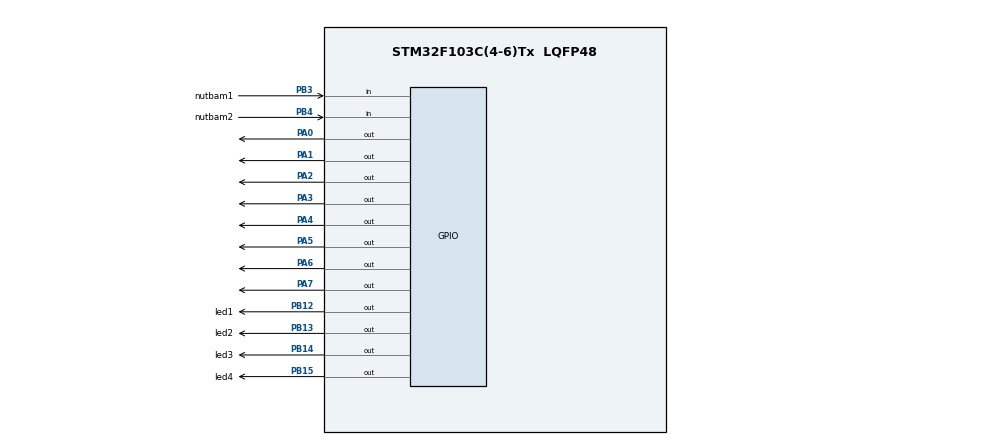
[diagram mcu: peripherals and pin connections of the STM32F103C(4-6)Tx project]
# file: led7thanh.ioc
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Mcu.Family=STM32F1
Mcu.Name=STM32F103C(4-6)Tx
Mcu.Package=LQFP48
NVIC.PriorityGroup=NVIC_PRIORITYGROUP_4
PA0-WKUP.Signal=GPIO_Output
PA1.Signal=GPIO_Output
PA13.Mode=Serial_Wire
PA13.Signal=SYS_JTMS-SWDIO
PA14.Mode=Serial_Wire
PA14.Signal=SYS_JTCK-SWCLK
PA2.Signal=GPIO_Output
PA3.Signal=GPIO_Output
PA4.Signal=GPIO_Output
PA5.Signal=GPIO_Output
PA6.Signal=GPIO_Output
PA7.Signal=GPIO_Output
PB12.GPIO_Label=led1
PB12.PinState=GPIO_PIN_SET
PB12.Signal=GPIO_Output
PB13.GPIO_Label=led2
PB13.PinState=GPIO_PIN_SET
PB13.Signal=GPIO_Output
PB14.GPIO_Label=led3
PB14.PinState=GPIO_PIN_SET
PB14.Signal=GPIO_Output
PB15.GPIO_Label=led4
PB15.PinState=GPIO_PIN_SET
PB15.Signal=GPIO_Output
PB3.GPIO_Label=nutbam1
PB3.Signal=GPIO_Input
PB4.GPIO_Label=nutbam2
PB4.Signal=GPIO_Input
ProjectManager.HeapSize=0x200
ProjectManager.StackSize=0x400
ProjectManager.TargetToolchain=MDK-ARM V5
RCC.APB1Freq_Value=8000000
RCC.APB2Freq_Value=8000000
board=custom

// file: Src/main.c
/**
  ******************************************************************************
  * @file           : main.c
  * @brief          : Main program body
  ******************************************************************************
  ** This notice applies to any and all portions of this file
  * that are not between comment pairs USER CODE BEGIN and
  * USER CODE END. Other portions of this file, whether
  * inserted by the user or by software development tools
  * are owned by their respective copyright owners.
  *
  * COPYRIGHT(c) 2018 STMicroelectronics
  *
  * Redistribution and use in source and binary forms, with or without modification,
  * are permitted provided that the following conditions are met:
  *   1. Redistributions of source code must retain the above copyright notice,
  *      this list of conditions and the following disclaimer.
  *   2. Redistributions in binary form must reproduce the above copyright notice,
  *      this list of conditions and the following disclaimer in the documentation
  *      and/or other materials provided with the distribution.
  *   3. Neither the name of STMicroelectronics nor the names of its contributors
  *      may be used to endorse or promote products derived from this software
  *      without specific prior written permission.
  *
  * THIS SOFTWARE IS PROVIDED BY THE COPYRIGHT HOLDERS AND CONTRIBUTORS "AS IS"
  * AND ANY EXPRESS OR IMPLIED WARRANTIES, INCLUDING, BUT NOT LIMITED TO, THE
  * IMPLIED WARRANTIES OF MERCHANTABILITY AND FITNESS FOR A PARTICULAR PURPOSE ARE
  * DISCLAIMED. IN NO EVENT SHALL THE COPYRIGHT HOLDER OR CONTRIBUTORS BE LIABLE
  * FOR ANY DIRECT, INDIRECT, INCIDENTAL, SPECIAL, EXEMPLARY, OR CONSEQUENTIAL
  * DAMAGES (INCLUDING, BUT NOT LIMITED TO, PROCUREMENT OF SUBSTITUTE GOODS OR
  * SERVICES; LOSS OF USE, DATA, OR PROFITS; OR BUSINESS INTERRUPTION) HOWEVER
  * CAUSED AND ON ANY THEORY OF LIABILITY, WHETHER IN CONTRACT, STRICT LIABILITY,
  * OR TORT (INCLUDING NEGLIGENCE OR OTHERWISE) ARISING IN ANY WAY OUT OF THE USE
  * OF THIS SOFTWARE, EVEN IF ADVISED OF THE POSSIBILITY OF SUCH DAMAGE.
  *
  ******************************************************************************
  */
#include "main.h"
#include "stm32f1xx_hal.h"

/* USER CODE BEGIN PV */
/* Private variables ---------------------------------------------------------*/

uint8_t ledCode[10] = {0xC0, 0xF9, 0xA4, 0xB0, 0x99, 0x92, 0x82, 0xF8, 0x80, 0x90};

/* USER CODE END PV */

void SystemClock_Config(void);
static void MX_GPIO_Init(void);

/* USER CODE BEGIN PFP */
/* Private function prototypes -----------------------------------------------*/

/* USER CODE END PFP */

int main(void)
{
  /* USER CODE BEGIN 1 */
  uint8_t i = 0;

  /* USER CODE END 1 */

  /* MCU Configuration----------------------------------------------------------*/

  /* Reset of all peripherals, Initializes the Flash interface and the Systick. */
  HAL_Init();

  /* Configure the system clock */
  SystemClock_Config();

  /* Initialize all configured peripherals */
  MX_GPIO_Init();
  /* USER CODE BEGIN 2 */
  HAL_GPIO_WritePin (led1_GPIO_Port ,led1_Pin ,0);
  HAL_GPIO_WritePin (led2_GPIO_Port ,led2_Pin ,1);
  HAL_GPIO_WritePin (led3_GPIO_Port ,led3_Pin ,0);
  HAL_GPIO_WritePin (led4_GPIO_Port ,led4_Pin ,0);
  /* USER CODE END 2 */

  /* Infinite loop */
  /* USER CODE BEGIN WHILE */
  while (1)
  {
    /*for (i = 0; i<=9;i++)
    {
    GPIOA ->ODR = ledCode[i];
    HAL_Delay(500);
    }*/
    GPIOA ->ODR = ledCode[i];

    if (HAL_GPIO_ReadPin (nutbam1_GPIO_Port, nutbam1_Pin) ==0)
    {
      i = i++; if i==10 i=0;
      GPIOA ->ODR = ledCode[i];
    }

     if (HAL_GPIO_ReadPin (nutbam2_GPIO_Port, nutbam2_Pin) ==0)
    {
      i = i--;
      if i==0 i=9;
      GPIOA ->ODR = ledCode[i];
    }
  /* USER CODE END WHILE */

  }

}

void SystemClock_Config(void)
{

  RCC_OscInitTypeDef RCC_OscInitStruct;
  RCC_ClkInitTypeDef RCC_ClkInitStruct;

    /**Initializes the CPU, AHB and APB busses clocks
    */
  RCC_OscInitStruct.OscillatorType = RCC_OSCILLATORTYPE_HSI;
  RCC_OscInitStruct.HSIState = RCC_HSI_ON;
  RCC_OscInitStruct.HSICalibrationValue = 16;
  RCC_OscInitStruct.PLL.PLLState = RCC_PLL_NONE;
  if (HAL_RCC_OscConfig(&RCC_OscInitStruct) != HAL_OK)
  {
    _Error_Handler(__FILE__, __LINE__);
  }

    /**Initializes the CPU, AHB and APB busses clocks
    */
  RCC_ClkInitStruct.ClockType = RCC_CLOCKTYPE_HCLK|RCC_CLOCKTYPE_SYSCLK
                              |RCC_CLOCKTYPE_PCLK1|RCC_CLOCKTYPE_PCLK2;
  RCC_ClkInitStruct.SYSCLKSource = RCC_SYSCLKSOURCE_HSI;
  RCC_ClkInitStruct.AHBCLKDivider = RCC_SYSCLK_DIV1;
  RCC_ClkInitStruct.APB1CLKDivider = RCC_HCLK_DIV1;
  RCC_ClkInitStruct.APB2CLKDivider = RCC_HCLK_DIV1;

  if (HAL_RCC_ClockConfig(&RCC_ClkInitStruct, FLASH_LATENCY_0) != HAL_OK)
  {
    _Error_Handler(__FILE__, __LINE__);
  }

    /**Configure the Systick interrupt time
    */
  HAL_SYSTICK_Config(HAL_RCC_GetHCLKFreq()/1000);

    /**Configure the Systick
    */
  HAL_SYSTICK_CLKSourceConfig(SYSTICK_CLKSOURCE_HCLK);

  /* SysTick_IRQn interrupt configuration */
  HAL_NVIC_SetPriority(SysTick_IRQn, 0, 0);
}

/** Configure pins as
        * Analog
        * Input
        * Output
        * EVENT_OUT
        * EXTI
*/
static void MX_GPIO_Init(void)
{

  GPIO_InitTypeDef GPIO_InitStruct;

  /* GPIO Ports Clock Enable */
  __HAL_RCC_GPIOA_CLK_ENABLE();
  __HAL_RCC_GPIOB_CLK_ENABLE();

  /*Configure GPIO pin Output Level */
  HAL_GPIO_WritePin(GPIOA, GPIO_PIN_0|GPIO_PIN_1|GPIO_PIN_2|GPIO_PIN_3
                          |GPIO_PIN_4|GPIO_PIN_5|GPIO_PIN_6|GPIO_PIN_7, GPIO_PIN_RESET);

  /*Configure GPIO pin Output Level */
  HAL_GPIO_WritePin(GPIOB, led1_Pin|led2_Pin|led3_Pin|led4_Pin, GPIO_PIN_SET);

  /*Configure GPIO pins : PA0 PA1 PA2 PA3
                           PA4 PA5 PA6 PA7 */
  GPIO_InitStruct.Pin = GPIO_PIN_0|GPIO_PIN_1|GPIO_PIN_2|GPIO_PIN_3
                          |GPIO_PIN_4|GPIO_PIN_5|GPIO_PIN_6|GPIO_PIN_7;
  GPIO_InitStruct.Mode = GPIO_MODE_OUTPUT_PP;
  GPIO_InitStruct.Pull = GPIO_NOPULL;
  GPIO_InitStruct.Speed = GPIO_SPEED_FREQ_LOW;
  HAL_GPIO_Init(GPIOA, &GPIO_InitStruct);

  /*Configure GPIO pins : led1_Pin led2_Pin led3_Pin led4_Pin */
  GPIO_InitStruct.Pin = led1_Pin|led2_Pin|led3_Pin|led4_Pin;
  GPIO_InitStruct.Mode = GPIO_MODE_OUTPUT_PP;
  GPIO_InitStruct.Pull = GPIO_NOPULL;
  GPIO_InitStruct.Speed = GPIO_SPEED_FREQ_LOW;
  HAL_GPIO_Init(GPIOB, &GPIO_InitStruct);

  /*Configure GPIO pins : nutbam1_Pin nutbam2_Pin */
  GPIO_InitStruct.Pin = nutbam1_Pin|nutbam2_Pin;
  GPIO_InitStruct.Mode = GPIO_MODE_INPUT;
  GPIO_InitStruct.Pull = GPIO_NOPULL;
  HAL_GPIO_Init(GPIOB, &GPIO_InitStruct);

}

void _Error_Handler(char *file, int line)
{
  while(1)
  {
  }
}

/************************ (C) COPYRIGHT STMicroelectronics *****END OF FILE****/
